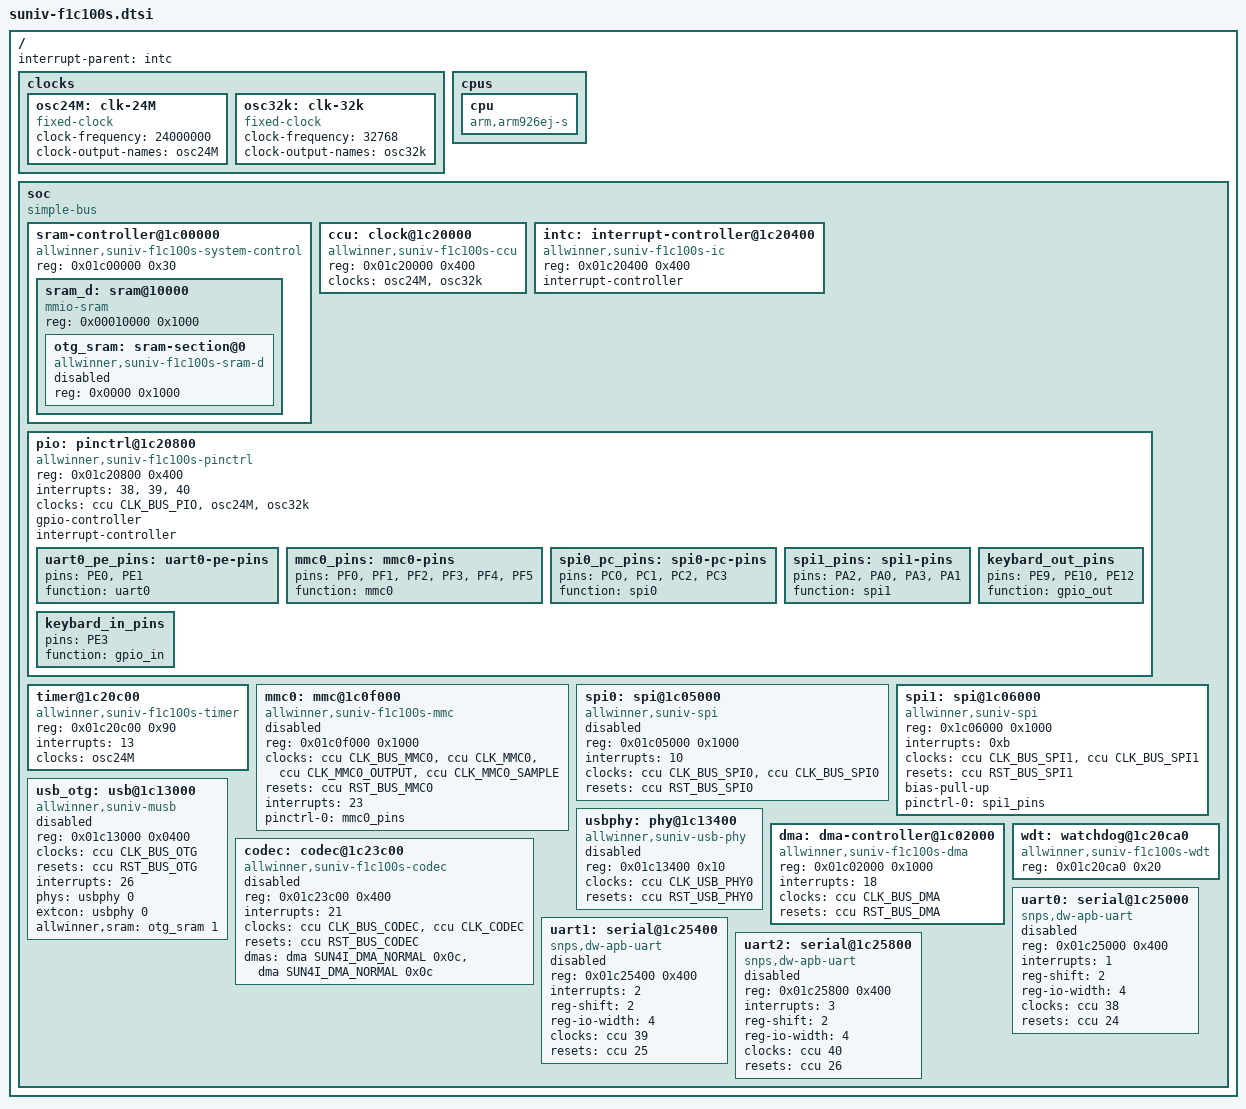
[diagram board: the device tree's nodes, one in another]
// SPDX-License-Identifier: (GPL-2.0+ OR X11)
/*
 * Copyright 2018 Icenowy Zheng <icenowy@aosc.io>
 * Copyright 2018 Mesih Kilinc <mesihkilinc@gmail.com>
 */

//my
#include <dt-bindings/clock/suniv-ccu-f1c100s.h>
#include <dt-bindings/reset/suniv-ccu-f1c100s.h>
#include <dt-bindings/dma/sun4i-a10.h> //添加 sound 头文件
/ {
	#address-cells = <1>;
	#size-cells = <1>;
	interrupt-parent = <&intc>;

	clocks {
		osc24M: clk-24M {
			#clock-cells = <0>;
			compatible = "fixed-clock";
			clock-frequency = <24000000>;
			clock-output-names = "osc24M";
		};

		osc32k: clk-32k {
			#clock-cells = <0>;
			compatible = "fixed-clock";
			clock-frequency = <32768>;
			clock-output-names = "osc32k";
		};
	};

	cpus {
		cpu {
			compatible = "arm,arm926ej-s";
			device_type = "cpu";
		};
	};

	soc {
		compatible = "simple-bus";
		#address-cells = <1>;
		#size-cells = <1>;
		ranges;

		sram-controller@1c00000 {
			compatible = "allwinner,suniv-f1c100s-system-control",
				     "allwinner,sun4i-a10-system-control";
			reg = <0x01c00000 0x30>;
			#address-cells = <1>;
			#size-cells = <1>;
			ranges;

			sram_d: sram@10000 {
				compatible = "mmio-sram";
				reg = <0x00010000 0x1000>;
				#address-cells = <1>;
				#size-cells = <1>;
				ranges = <0 0x00010000 0x1000>;

				otg_sram: sram-section@0 {
					compatible = "allwinner,suniv-f1c100s-sram-d",
						     "allwinner,sun4i-a10-sram-d";
					reg = <0x0000 0x1000>;
					status = "disabled";
				};
			};
		};

		ccu: clock@1c20000 {
			compatible = "allwinner,suniv-f1c100s-ccu";
			reg = <0x01c20000 0x400>;
			clocks = <&osc24M>, <&osc32k>;
			clock-names = "hosc", "losc";
			#clock-cells = <1>;
			#reset-cells = <1>;
		};

		intc: interrupt-controller@1c20400 {
			compatible = "allwinner,suniv-f1c100s-ic";
			reg = <0x01c20400 0x400>;
			interrupt-controller;
			#interrupt-cells = <1>;
		};

		pio: pinctrl@1c20800 {
			compatible = "allwinner,suniv-f1c100s-pinctrl";
			reg = <0x01c20800 0x400>;
			interrupts =<38>,<39>,<40>;
			clocks = <&ccu CLK_BUS_PIO>, <&osc24M>, <&osc32k>;
			clock-names = "apb", "hosc", "losc";
			gpio-controller;
			interrupt-controller;
			#interrupt-cells =<3>;
			#gpio-cells =<3>;

			uart0_pe_pins: uart0-pe-pins {
				pins = "PE0", "PE1";
				function = "uart0";
			};

			//my MMC控制器 SD卡
			mmc0_pins: mmc0-pins {
                pins = "PF0", "PF1", "PF2", "PF3", "PF4", "PF5";
                function = "mmc0";
            };

			//my esp8266
			spi0_pc_pins: spi0-pc-pins {
                pins = "PC0","PC1","PC2","PC3";
                function = "spi0";
            };

			//my screen
			spi1_pins: spi1-pins{
				pins = "PA2","PA0","PA3","PA1";
				function = "spi1";
			};

			//my io
			/* 
			* 第一个子节点：负责输出（gpio_out），包含 PE6、PE11 
			*/
			keybard_out_pins: keybard_out_pins {
				pins = "PE9", "PE10", "PE12";
				function = "gpio_out";
				/* 如果需要内部上下拉等，可以再加 bias-pull-up / bias-pull-down 等属性 */
			};

			/*
			* 第二个子节点：负责输入（gpio_in），包含 PE3 
			*/
			keybard_in_pins: keybard_in_pins {
				pins = "PE3";
				function = "gpio_in";
				/* 若需要内部上拉： bias-pull-up; */
			};

		};

		timer@1c20c00 {
			compatible = "allwinner,suniv-f1c100s-timer";
			reg = <0x01c20c00 0x90>;
			interrupts = <13>;
			clocks = <&osc24M>;
		};

		//my MMC控制器 SD卡
		mmc0: mmc@1c0f000 {
            compatible = "allwinner,suniv-f1c100s-mmc",
                     "allwinner,sun7i-a20-mmc";
            reg = <0x01c0f000 0x1000>;
            clocks = <&ccu CLK_BUS_MMC0>,
                 <&ccu CLK_MMC0>,
                 <&ccu CLK_MMC0_OUTPUT>,
                 <&ccu CLK_MMC0_SAMPLE>;
            clock-names = "ahb",
                          "mmc",
                          "output",
                          "sample";
            resets = <&ccu RST_BUS_MMC0>;
            reset-names = "ahb";
            interrupts = <23>;
            pinctrl-names = "default";
            pinctrl-0 = <&mmc0_pins>;
            status = "disabled";
            #address-cells = <1>;
            #size-cells = <0>;
        };

		//my esp8266
		spi0: spi@1c05000 {
            compatible = "allwinner,suniv-spi",
                     "allwinner,sun8i-h3-spi";
            reg = <0x01c05000 0x1000>;
            interrupts = <10>;
            clocks = <&ccu CLK_BUS_SPI0>, <&ccu CLK_BUS_SPI0>;
            clock-names = "ahb", "mod";
            resets = <&ccu RST_BUS_SPI0>;
            status = "disabled";
            #address-cells = <1>;
            #size-cells = <0>;
        };

		//my screen 
		spi1:spi@1c06000 {
            compatible = "allwinner,suniv-spi", "allwinner,sun8i-h3-spi";
            reg =<0x1c06000 0x1000>;
            interrupts =<0xb>;
            clocks = <&ccu CLK_BUS_SPI1>, <&ccu CLK_BUS_SPI1>;
            clock-names = "ahb", "mod";
            resets = <&ccu RST_BUS_SPI1>;
            status = "okay";
            #address-cells =<1>;
            #size-cells =<0>;
            bias-pull-up;
            pinctrl-names = "default";
            pinctrl-0 = <&spi1_pins>;
        };

		//my USB
		usb_otg: usb@1c13000 {
			compatible = "allwinner,suniv-musb";
			reg = <0x01c13000 0x0400>;
			clocks = <&ccu CLK_BUS_OTG>;
			resets = <&ccu RST_BUS_OTG>;
			interrupts = <26>;
			interrupt-names = "mc";
			phys = <&usbphy 0>;
			phy-names = "usb";
			extcon = <&usbphy 0>;
			allwinner,sram = <&otg_sram 1>;
			status = "disabled";
		};

		//my USB
		usbphy: phy@1c13400 {
			compatible = "allwinner,suniv-usb-phy";
			reg = <0x01c13400 0x10>;
			reg-names = "phy_ctrl";
			clocks = <&ccu CLK_USB_PHY0>;
			clock-names = "usb0_phy";
			resets = <&ccu RST_USB_PHY0>;
			reset-names = "usb0_reset";
			#phy-cells = <1>;
			status = "disabled";
		};

		//my sound
		dma: dma-controller@1c02000 {
			compatible = "allwinner,suniv-f1c100s-dma";
			reg = <0x01c02000 0x1000>;
			interrupts = <18>;
			clocks = <&ccu CLK_BUS_DMA>;
			resets = <&ccu RST_BUS_DMA>;
			#dma-cells = <2>;
		};

		//my sound
		codec: codec@1c23c00 {
			compatible = "allwinner,suniv-f1c100s-codec";
			reg = <0x01c23c00 0x400>;
			interrupts = <21>;
			clocks = <&ccu CLK_BUS_CODEC>,
				<&ccu CLK_CODEC>;
			clock-names = "apb", "codec";
			resets = <&ccu RST_BUS_CODEC>;
			dmas = <&dma SUN4I_DMA_NORMAL 0x0c>, 
				<&dma SUN4I_DMA_NORMAL 0x0c>;
			dma-names = "rx", "tx";
			status = "disabled";
		};



		wdt: watchdog@1c20ca0 {
			compatible = "allwinner,suniv-f1c100s-wdt",
				     "allwinner,sun4i-a10-wdt";
			reg = <0x01c20ca0 0x20>;
		};

		uart0: serial@1c25000 {
			compatible = "snps,dw-apb-uart";
			reg = <0x01c25000 0x400>;
			interrupts = <1>;
			reg-shift = <2>;
			reg-io-width = <4>;
			clocks = <&ccu 38>;
			resets = <&ccu 24>;
			status = "disabled";
		};

		uart1: serial@1c25400 {
			compatible = "snps,dw-apb-uart";
			reg = <0x01c25400 0x400>;
			interrupts = <2>;
			reg-shift = <2>;
			reg-io-width = <4>;
			clocks = <&ccu 39>;
			resets = <&ccu 25>;
			status = "disabled";
		};

		uart2: serial@1c25800 {
			compatible = "snps,dw-apb-uart";
			reg = <0x01c25800 0x400>;
			interrupts = <3>;
			reg-shift = <2>;
			reg-io-width = <4>;
			clocks = <&ccu 40>;
			resets = <&ccu 26>;
			status = "disabled";
		};
	};
};
